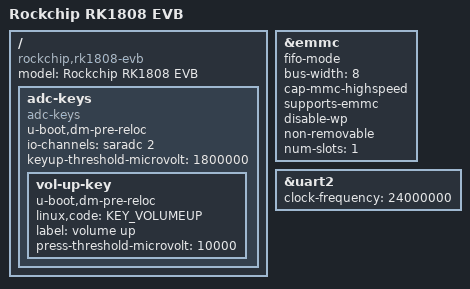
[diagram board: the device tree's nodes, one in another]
// SPDX-License-Identifier:     GPL-2.0+
/*
 * (C) Copyright 2018 Rockchip Electronics Co., Ltd
 *
 */

/dts-v1/;
#include "rk1808.dtsi"
#include "rk1808-u-boot.dtsi"
#include <dt-bindings/input/input.h>
#include <linux/media-bus-format.h>

/ {
	model = "Rockchip RK1808 EVB";
	compatible = "rockchip,rk1808-evb", "rockchip,rk1808";

	adc-keys {
		status = "okay";

		u-boot,dm-pre-reloc;
		compatible = "adc-keys";
		io-channels = <&saradc 2>;
		io-channel-names = "buttons";
		keyup-threshold-microvolt = <1800000>;

		vol-up-key {
			u-boot,dm-pre-reloc;
			linux,code = <KEY_VOLUMEUP>;
			label = "volume up";
			press-threshold-microvolt = <10000>;
		};
	};
};

&emmc {
	fifo-mode;
	bus-width = <8>;
	cap-mmc-highspeed;
	supports-emmc;
	disable-wp;
	non-removable;
	num-slots = <1>;

	status = "okay";
};

&uart2 {
	clock-frequency = <24000000>;
	status = "okay";
};
